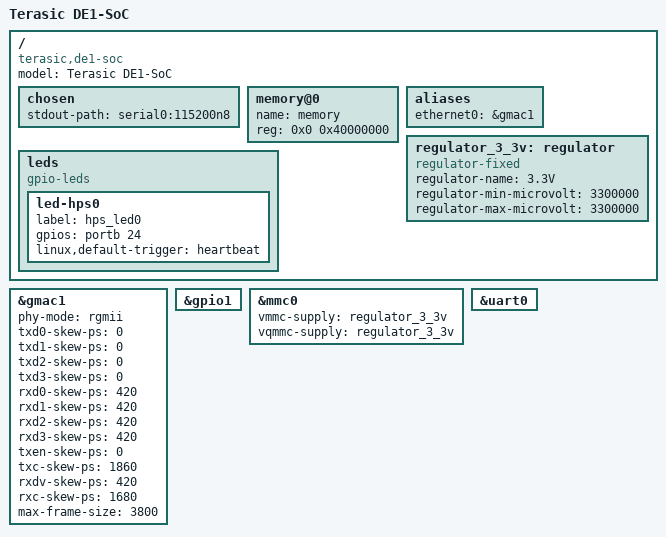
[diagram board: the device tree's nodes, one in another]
// SPDX-License-Identifier: GPL-2.0
/*
 * Terasic DE1-SoC, CPU-only baseline. Linux v6.12 has no DTS for this board, so this is derived
 * from socfpga_cyclone5_de0_nano_soc.dts, which uses the same HPS UART, SD and Ethernet wiring.
 * FPGA bridges and the accelerator are not described here yet.
 */
#include "socfpga_cyclone5.dtsi"

/ {
	model = "Terasic DE1-SoC";
	compatible = "terasic,de1-soc", "altr,socfpga-cyclone5", "altr,socfpga";

	chosen {
		stdout-path = "serial0:115200n8";
	};

	memory@0 {
		name = "memory";
		device_type = "memory";
		reg = <0x0 0x40000000>; /* 1GB */
	};

	aliases {
		ethernet0 = &gmac1;
	};

	regulator_3_3v: regulator {
		compatible = "regulator-fixed";
		regulator-name = "3.3V";
		regulator-min-microvolt = <3300000>;
		regulator-max-microvolt = <3300000>;
	};

	leds {
		compatible = "gpio-leds";
		led-hps0 {
			label = "hps_led0";
			gpios = <&portb 24 0>;
			linux,default-trigger = "heartbeat";
		};
	};
};

&gmac1 {
	status = "okay";
	phy-mode = "rgmii";

	txd0-skew-ps = <0>;
	txd1-skew-ps = <0>;
	txd2-skew-ps = <0>;
	txd3-skew-ps = <0>;
	rxd0-skew-ps = <420>;
	rxd1-skew-ps = <420>;
	rxd2-skew-ps = <420>;
	rxd3-skew-ps = <420>;
	txen-skew-ps = <0>;
	txc-skew-ps = <1860>;
	rxdv-skew-ps = <420>;
	rxc-skew-ps = <1680>;

	max-frame-size = <3800>;
};

&gpio1 {
	status = "okay";
};

&mmc0 {
	vmmc-supply = <&regulator_3_3v>;
	vqmmc-supply = <&regulator_3_3v>;
	status = "okay";
};

&uart0 {
	status = "okay";
};
